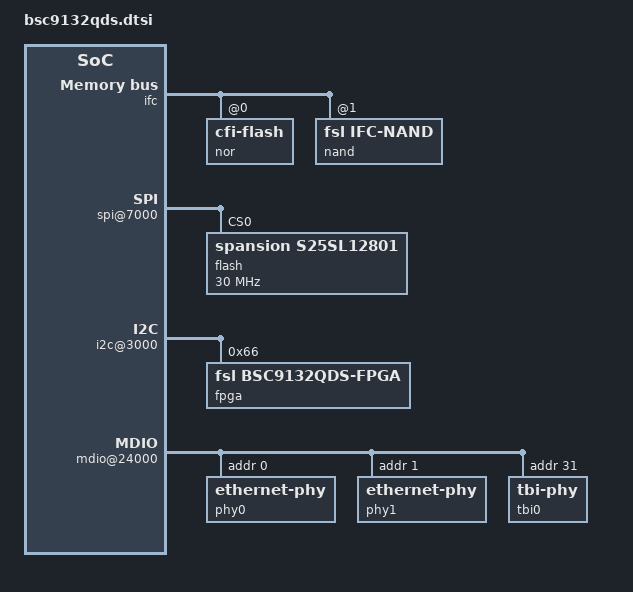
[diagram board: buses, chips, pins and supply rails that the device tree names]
&ifc {
	nor@0,0 {
		#address-cells = <1>;
		#size-cells = <1>;
		compatible = "cfi-flash";
		reg = <0x0 0x0 0x8000000>;
		bank-width = <2>;
		device-width = <1>;
	};
	nand@1,0 {
		#address-cells = <1>;
		#size-cells = <1>;
		compatible = "fsl,ifc-nand";
		reg = <0x1 0x0 0x4000>;
	};
};
&soc {
	spi@7000 {
		flash@0 {
			#address-cells = <1>;
			#size-cells = <1>;
			compatible = "spansion,s25sl12801", "jedec,spi-nor";
			reg = <0>;
			spi-max-frequency = <30000000>;
		};
	};
	i2c@3000 {
		fpga: fpga@66 {
			compatible = "fsl,bsc9132qds-fpga", "fsl,fpga-qixis-i2c";
			reg = <0x66>;
		};
	};
	usb@22000 {
		phy_type = "ulpi";
	};
	mdio@24000 {
		phy0: ethernet-phy@0 {
			reg = <0x0>;
		};
		phy1: ethernet-phy@1 {
			reg = <0x1>;
		};
		tbi0: tbi-phy@11 {
			reg = <0x1f>;
			device_type = "tbi-phy";
		};
	};
	ptp_clock@b0e00 {
		compatible = "fsl,etsec-ptp";
		reg = <0xb0e00 0xb0>;
		interrupts = <68 2 0 0 69 2 0 0>;
		fsl,tclk-period	= <5>;
		fsl,tmr-prsc	= <2>;
		fsl,tmr-add	= <0xcccccccd>;
		fsl,tmr-fiper1	= <999999995>;
		fsl,tmr-fiper2	= <99990>;
		fsl,max-adj	= <249999999>;
	};
	enet0: ethernet@b0000 {
		phy-handle = <&phy0>;
		tbi-handle = <&tbi0>;
		phy-connection-type = "sgmii";
	};
	enet1: ethernet@b1000 {
		phy-handle = <&phy1>;
		tbi-handle = <&tbi0>;
		phy-connection-type = "sgmii";
	};
};
